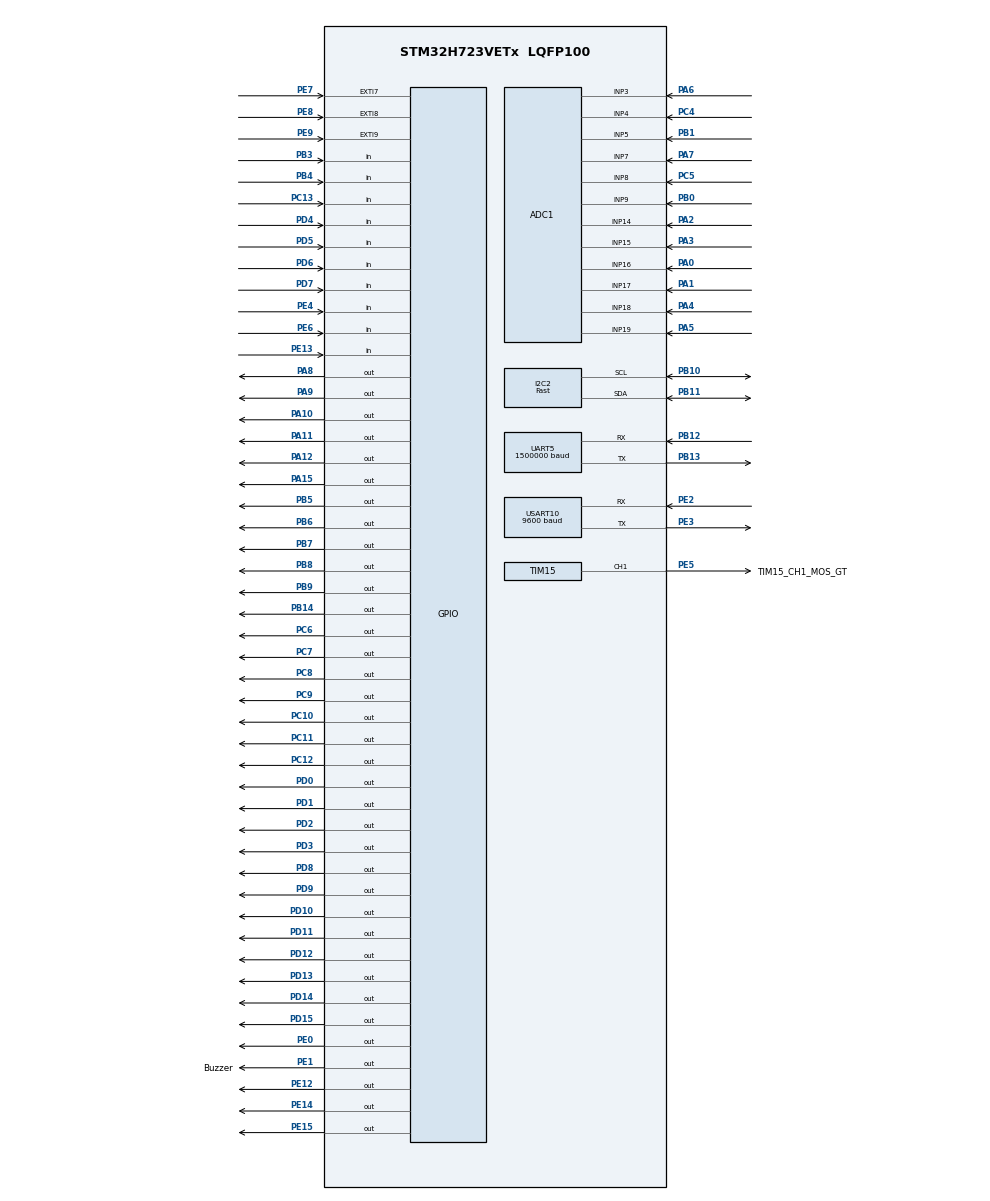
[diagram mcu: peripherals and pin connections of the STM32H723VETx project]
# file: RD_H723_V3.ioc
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ADC1.Channel-0\#ChannelRegularConversion=ADC_CHANNEL_5
ADC1.Channel-1\#ChannelRegularConversion=ADC_CHANNEL_16
ADC1.Channel-10\#ChannelRegularConversion=ADC_CHANNEL_9
ADC1.Channel-11\#ChannelRegularConversion=ADC_CHANNEL_3
ADC1.Channel-2\#ChannelRegularConversion=ADC_CHANNEL_17
ADC1.Channel-3\#ChannelRegularConversion=ADC_CHANNEL_14
ADC1.Channel-4\#ChannelRegularConversion=ADC_CHANNEL_15
ADC1.Channel-5\#ChannelRegularConversion=ADC_CHANNEL_18
ADC1.Channel-6\#ChannelRegularConversion=ADC_CHANNEL_19
ADC1.Channel-7\#ChannelRegularConversion=ADC_CHANNEL_8
ADC1.Channel-8\#ChannelRegularConversion=ADC_CHANNEL_7
ADC1.Channel-9\#ChannelRegularConversion=ADC_CHANNEL_4
ADC1.ClockPrescaler=ADC_CLOCK_ASYNC_DIV4
ADC1.ConversionDataManagement=ADC_CONVERSIONDATA_DMA_ONESHOT
ADC1.ExternalTrigConv=ADC_EXTERNALTRIG_T6_TRGO
ADC1.NbrOfConversion=12
ADC1.NbrOfConversionFlag=1
ADC1.OffsetNumber-0\#ChannelRegularConversion=ADC_OFFSET_NONE
ADC1.OffsetNumber-1\#ChannelRegularConversion=ADC_OFFSET_NONE
ADC1.OffsetNumber-10\#ChannelRegularConversion=ADC_OFFSET_NONE
ADC1.OffsetNumber-11\#ChannelRegularConversion=ADC_OFFSET_NONE
ADC1.OffsetNumber-2\#ChannelRegularConversion=ADC_OFFSET_NONE
ADC1.OffsetNumber-3\#ChannelRegularConversion=ADC_OFFSET_NONE
ADC1.OffsetNumber-4\#ChannelRegularConversion=ADC_OFFSET_NONE
ADC1.OffsetNumber-5\#ChannelRegularConversion=ADC_OFFSET_NONE
ADC1.OffsetNumber-6\#ChannelRegularConversion=ADC_OFFSET_NONE
ADC1.OffsetNumber-7\#ChannelRegularConversion=ADC_OFFSET_NONE
ADC1.OffsetNumber-8\#ChannelRegularConversion=ADC_OFFSET_NONE
ADC1.OffsetNumber-9\#ChannelRegularConversion=ADC_OFFSET_NONE
ADC1.OffsetSignedSaturation-0\#ChannelRegularConversion=DISABLE
ADC1.OffsetSignedSaturation-1\#ChannelRegularConversion=DISABLE
ADC1.OffsetSignedSaturation-10\#ChannelRegularConversion=DISABLE
ADC1.OffsetSignedSaturation-11\#ChannelRegularConversion=DISABLE
ADC1.OffsetSignedSaturation-2\#ChannelRegularConversion=DISABLE
ADC1.OffsetSignedSaturation-3\#ChannelRegularConversion=DISABLE
ADC1.OffsetSignedSaturation-4\#ChannelRegularConversion=DISABLE
ADC1.OffsetSignedSaturation-5\#ChannelRegularConversion=DISABLE
ADC1.OffsetSignedSaturation-6\#ChannelRegularConversion=DISABLE
ADC1.OffsetSignedSaturation-7\#ChannelRegularConversion=DISABLE
ADC1.OffsetSignedSaturation-8\#ChannelRegularConversion=DISABLE
ADC1.OffsetSignedSaturation-9\#ChannelRegularConversion=DISABLE
ADC1.Rank-0\#ChannelRegularConversion=1
ADC1.Rank-1\#ChannelRegularConversion=2
ADC1.Rank-10\#ChannelRegularConversion=11
ADC1.Rank-11\#ChannelRegularConversion=12
ADC1.Rank-2\#ChannelRegularConversion=3
ADC1.Rank-3\#ChannelRegularConversion=4
ADC1.Rank-4\#ChannelRegularConversion=5
ADC1.Rank-5\#ChannelRegularConversion=6
ADC1.Rank-6\#ChannelRegularConversion=7
ADC1.Rank-7\#ChannelRegularConversion=8
ADC1.Rank-8\#ChannelRegularConversion=9
ADC1.Rank-9\#ChannelRegularConversion=10
ADC1.SamplingTime-0\#ChannelRegularConversion=ADC_SAMPLETIME_1CYCLE_5
ADC1.SamplingTime-1\#ChannelRegularConversion=ADC_SAMPLETIME_1CYCLE_5
ADC1.SamplingTime-10\#ChannelRegularConversion=ADC_SAMPLETIME_1CYCLE_5
ADC1.SamplingTime-11\#ChannelRegularConversion=ADC_SAMPLETIME_1CYCLE_5
ADC1.SamplingTime-2\#ChannelRegularConversion=ADC_SAMPLETIME_1CYCLE_5
ADC1.SamplingTime-3\#ChannelRegularConversion=ADC_SAMPLETIME_1CYCLE_5
ADC1.SamplingTime-4\#ChannelRegularConversion=ADC_SAMPLETIME_1CYCLE_5
ADC1.SamplingTime-5\#ChannelRegularConversion=ADC_SAMPLETIME_1CYCLE_5
ADC1.SamplingTime-6\#ChannelRegularConversion=ADC_SAMPLETIME_1CYCLE_5
ADC1.SamplingTime-7\#ChannelRegularConversion=ADC_SAMPLETIME_1CYCLE_5
ADC1.SamplingTime-8\#ChannelRegularConversion=ADC_SAMPLETIME_1CYCLE_5
ADC1.SamplingTime-9\#ChannelRegularConversion=ADC_SAMPLETIME_1CYCLE_5
ADC1.master=1
CORTEX_M7.CPU_ICache=Disabled
CORTEX_M7.default_mode_Activation=1
Dma.ADC1.1.Direction=DMA_PERIPH_TO_MEMORY
Dma.ADC1.1.EventEnable=DISABLE
Dma.ADC1.1.FIFOMode=DMA_FIFOMODE_DISABLE
Dma.ADC1.1.Instance=DMA1_Stream1
Dma.ADC1.1.MemDataAlignment=DMA_MDATAALIGN_HALFWORD
Dma.ADC1.1.MemInc=DMA_MINC_ENABLE
Dma.ADC1.1.Mode=DMA_NORMAL
Dma.ADC1.1.PeriphDataAlignment=DMA_PDATAALIGN_HALFWORD
Dma.ADC1.1.PeriphInc=DMA_PINC_DISABLE
Dma.ADC1.1.Polarity=HAL_DMAMUX_REQ_GEN_RISING
Dma.ADC1.1.Priority=DMA_PRIORITY_VERY_HIGH
Dma.ADC1.1.RequestNumber=1
Dma.ADC1.1.SignalID=NONE
Dma.ADC1.1.SyncEnable=DISABLE
Dma.ADC1.1.SyncPolarity=HAL_DMAMUX_SYNC_NO_EVENT
Dma.ADC1.1.SyncRequestNumber=1
Dma.ADC1.1.SyncSignalID=NONE
Dma.Request0=UART5_TX
Dma.Request1=ADC1
Dma.UART5_TX.0.Direction=DMA_MEMORY_TO_PERIPH
Dma.UART5_TX.0.EventEnable=DISABLE
Dma.UART5_TX.0.FIFOMode=DMA_FIFOMODE_DISABLE
Dma.UART5_TX.0.Instance=DMA1_Stream0
Dma.UART5_TX.0.MemDataAlignment=DMA_MDATAALIGN_BYTE
Dma.UART5_TX.0.MemInc=DMA_MINC_ENABLE
Dma.UART5_TX.0.Mode=DMA_NORMAL
Dma.UART5_TX.0.PeriphDataAlignment=DMA_PDATAALIGN_BYTE
Dma.UART5_TX.0.PeriphInc=DMA_PINC_DISABLE
Dma.UART5_TX.0.Polarity=HAL_DMAMUX_REQ_GEN_RISING
Dma.UART5_TX.0.Priority=DMA_PRIORITY_LOW
Dma.UART5_TX.0.RequestNumber=1
Dma.UART5_TX.0.SignalID=NONE
Dma.UART5_TX.0.SyncEnable=DISABLE
Dma.UART5_TX.0.SyncPolarity=HAL_DMAMUX_SYNC_NO_EVENT
Dma.UART5_TX.0.SyncRequestNumber=1
Dma.UART5_TX.0.SyncSignalID=NONE
I2C2.Analog_Filter=I2C_ANALOGFILTER_DISABLE
I2C2.I2C_Speed_Mode=I2C_Fast
I2C2.OwnAddress=111
I2C2.Timing=0x00D056FC
Mcu.Family=STM32H7
Mcu.Name=STM32H723VETx
Mcu.Package=LQFP100
NVIC.DMA1_Stream0_IRQn=true\:0\:0\:false\:false\:false\:false\:true\:true
NVIC.DMA1_Stream1_IRQn=true\:0\:0\:false\:false\:false\:false\:true\:true
NVIC.EXTI9_5_IRQn=true\:15\:0\:true\:false\:false\:true\:true\:true
NVIC.PriorityGroup=NVIC_PRIORITYGROUP_4
NVIC.TIM16_IRQn=true\:15\:0\:true\:false\:false\:true\:true\:true
NVIC.TIM1_UP_IRQn=true\:15\:0\:true\:false\:false\:true\:true\:true
NVIC.TIM23_IRQn=true\:15\:0\:true\:false\:false\:true\:true\:true
NVIC.TIM24_IRQn=true\:15\:0\:true\:false\:false\:true\:true\:true
NVIC.TIM2_IRQn=true\:15\:0\:true\:false\:false\:true\:true\:true
NVIC.TIM3_IRQn=true\:15\:0\:true\:false\:false\:true\:true\:true
NVIC.TIM7_IRQn=true\:15\:0\:true\:false\:false\:true\:true\:true
NVIC.USART10_IRQn=true\:15\:0\:true\:false\:false\:true\:true\:true
PA0.Mode=IN16-Single-Ended
PA0.Signal=ADC1_INP16
PA1.Mode=IN17-Single-Ended
PA1.Signal=ADC1_INP17
PA10.Signal=GPIO_Output
PA11.Signal=GPIO_Output
PA12.Signal=GPIO_Output
PA13(JTMS/SWDIO).Mode=Serial_Wire
PA13(JTMS/SWDIO).Signal=DEBUG_JTMS-SWDIO
PA14(JTCK/SWCLK).Mode=Serial_Wire
PA14(JTCK/SWCLK).Signal=DEBUG_JTCK-SWCLK
PA15(JTDI).Signal=GPIO_Output
PA2.Signal=ADCx_INP14
PA3.Signal=ADCx_INP15
PA4.Signal=ADCx_INP18
PA5.Signal=ADCx_INP19
PA6.Signal=ADCx_INP3
PA7.Signal=ADCx_INP7
PA8.Signal=GPIO_Output
PA9.Signal=GPIO_Output
PB0.Signal=ADCx_INP9
PB1.Signal=ADCx_INP5
PB10.Mode=I2C
PB10.Signal=I2C2_SCL
PB11.Mode=I2C
PB11.Signal=I2C2_SDA
PB12.GPIO_ModeDefaultPP=GPIO_MODE_AF_OD
PB12.GPIO_PuPd=GPIO_PULLDOWN
PB12.Mode=Asynchronous
PB12.Signal=UART5_RX
PB13.GPIO_ModeDefaultPP=GPIO_MODE_AF_PP
PB13.Mode=Asynchronous
PB13.Signal=UART5_TX
PB14.Signal=GPIO_Output
PB3(JTDO/TRACESWO).Signal=GPIO_Input
PB4(NJTRST).Signal=GPIO_Input
PB5.Signal=GPIO_Output
PB6.Signal=GPIO_Output
PB7.Signal=GPIO_Output
PB8.Signal=GPIO_Output
PB9.Signal=GPIO_Output
PC10.Signal=GPIO_Output
PC11.Signal=GPIO_Output
PC12.Signal=GPIO_Output
PC13.Signal=GPIO_Input
PC4.Signal=ADCx_INP4
PC5.Signal=ADCx_INP8
PC6.Signal=GPIO_Output
PC7.Signal=GPIO_Output
PC8.Signal=GPIO_Output
PC9.Signal=GPIO_Output
PD0.Signal=GPIO_Output
PD1.Signal=GPIO_Output
PD10.Signal=GPIO_Output
PD11.Signal=GPIO_Output
PD12.Signal=GPIO_Output
PD13.Signal=GPIO_Output
PD14.Signal=GPIO_Output
PD15.Signal=GPIO_Output
PD2.Signal=GPIO_Output
PD3.Signal=GPIO_Output
PD4.Signal=GPIO_Input
PD5.Signal=GPIO_Input
PD6.Signal=GPIO_Input
PD7.Signal=GPIO_Input
PD8.Signal=GPIO_Output
PD9.Signal=GPIO_Output
PE0.Signal=GPIO_Output
PE1.GPIO_Label=Buzzer
PE1.PinState=GPIO_PIN_RESET
PE1.Signal=GPIO_Output
PE12.PinState=GPIO_PIN_RESET
PE12.Signal=GPIO_Output
PE13.Signal=GPIO_Input
PE14.Signal=GPIO_Output
PE15.Signal=GPIO_Output
PE2.GPIO_PuPd=GPIO_PULLDOWN
PE2.Mode=Asynchronous
PE2.Signal=USART10_RX
PE3.Mode=Asynchronous
PE3.Signal=USART10_TX
PE4.Signal=GPIO_Input
PE5.GPIO_Label=TIM15_CH1_MOS_GT
PE5.Signal=S_TIM15_CH1
PE6.Signal=GPIO_Input
PE7.Signal=GPXTI7
PE8.Signal=GPXTI8
PE9.Signal=GPXTI9
ProjectManager.HeapSize=0x200
ProjectManager.StackSize=0x400
ProjectManager.TargetToolchain=STM32CubeIDE
RCC.ADCFreq_Value=96000000
RCC.APB1Freq_Value=137500000
RCC.APB2Freq_Value=137500000
RCC.APB3Freq_Value=137500000
RCC.APB4Freq_Value=137500000
RCC.CortexFreq_Value=550000000
RCC.D1PPRE=RCC_APB3_DIV2
RCC.D2PPRE1=RCC_APB1_DIV2
RCC.D2PPRE2=RCC_APB2_DIV2
RCC.D3PPRE=RCC_APB4_DIV2
RCC.DIVM1=4
RCC.DIVM2=4
RCC.DIVN1=34
RCC.DIVN2=12
RCC.DIVP1=1
RCC.HCLKFreq_Value=275000000
RCC.HPRE=RCC_HCLK_DIV2
RCC.PLL2FRACN=0
RCC.PLL3FRACN=0
RCC.PLLFRACN=3072
RCC.SPI123CLockSelection=RCC_SPI123CLKSOURCE_CLKP
RCC.SYSCLKFreq_VALUE=550000000
RCC.SYSCLKSource=RCC_SYSCLKSOURCE_PLLCLK
RCC.Spi45ClockSelection=RCC_SPI45CLKSOURCE_HSI
RCC.USBFreq_Value=275000000
SH.ADCx_INP14.0=ADC1_INP14,IN14-Single-Ended
SH.ADCx_INP15.0=ADC1_INP15,IN15-Single-Ended
SH.ADCx_INP18.0=ADC1_INP18,IN18-Single-Ended
SH.ADCx_INP19.0=ADC1_INP19,IN19-Single-Ended
SH.ADCx_INP3.0=ADC1_INP3,IN3-Single-Ended
SH.ADCx_INP4.0=ADC1_INP4,IN4-Single-Ended
SH.ADCx_INP5.0=ADC1_INP5,IN5-Single-Ended
SH.ADCx_INP7.0=ADC1_INP7,IN7-Single-Ended
SH.ADCx_INP8.0=ADC1_INP8,IN8-Single-Ended
SH.ADCx_INP9.0=ADC1_INP9,IN9-Single-Ended
SH.S_TIM15_CH1.0=TIM15_CH1,PWM Generation1 CH1
TIM15.AutoReloadPreload=TIM_AUTORELOAD_PRELOAD_ENABLE
TIM15.Channel-PWM\ Generation1\ CH1=TIM_CHANNEL_1
TIM15.Pulse-PWM\ Generation1\ CH1=10000
TIM16.Channel=TIM_CHANNEL_1
TIM6.Period=54999
TIM6.Prescaler=4
TIM6.TIM_MasterOutputTrigger=TIM_TRGO_UPDATE
UART5.BaudRate=1500000
USART10.BaudRate=9600
USART10.SwapParam=ADVFEATURE_SWAP_ENABLE
USART10.VirtualMode=VM_ASYNC
VP_MEMORYMAP_VS_MEMORYMAP.Mode=CurAppReg
VP_TIM16_VS_ClockSourceINT.Mode=Enable_Timer
VP_TIM16_VS_no_output1.Mode=PWM Generation1 No Output
VP_TIM1_VS_ClockSourceINT.Mode=Internal
VP_TIM23_VS_ClockSourceINT.Mode=Internal
VP_TIM24_VS_ClockSourceINT.Mode=Internal
VP_TIM2_VS_ClockSourceINT.Mode=Internal
VP_TIM3_VS_ClockSourceINT.Mode=Internal
VP_TIM5_VS_ClockSourceINT.Mode=Internal
VP_TIM6_VS_ClockSourceINT.Mode=Enable_Timer
VP_TIM7_VS_ClockSourceINT.Mode=Enable_Timer
board=custom

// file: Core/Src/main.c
/* USER CODE BEGIN Header */
/**
  ******************************************************************************
  * @file           : main.c
  * @brief          : Main program body
  ******************************************************************************
  * @attention
  *
  * Copyright (c) 2024 STMicroelectronics.
  * All rights reserved.
  *
  * This software is licensed under terms that can be found in the LICENSE file
  * in the root directory of this software component.
  * If no LICENSE file comes with this software, it is provided AS-IS.
  *
  ******************************************************************************
  */
#include "_Includes.h"					////////////////////////////////////////////////////////
/* USER CODE END Header */
#include "main.h"

/* USER CODE BEGIN Includes */
#include "_DefConst_OK.h"					////////////////////////////////////////////////////////
#include "_DefConst.h"					////////////////////////////////////////////////////////
#include "_Fnc_Gen.h"					////////////////////////////////////////////////////////
#include "_Fnc_IRQ.h"					////////////////////////////////////////////////////////
/* USER CODE END Includes */

UART_HandleTypeDef huart10;

void SystemClock_Config(void);
void PeriphCommonClock_Config(void);
static void MPU_Config(void);
static void MX_GPIO_Init(void);
static void MX_DMA_Init(void);
static void MX_TIM15_Init(void);
static void MX_UART5_Init(void);
static void MX_TIM7_Init(void);
static void MX_I2C2_Init(void);
static void MX_ADC1_Init(void);
static void MX_TIM2_Init(void);
static void MX_TIM3_Init(void);
static void MX_TIM5_Init(void);
static void MX_TIM6_Init(void);
static void MX_TIM16_Init(void);
static void MX_TIM23_Init(void);
static void MX_TIM24_Init(void);
static void MX_USART10_UART_Init(void);
static void MX_TIM1_Init(void);

int main(void)
{

  /* MPU Configuration--------------------------------------------------------*/
  MPU_Config();

  /* MCU Configuration--------------------------------------------------------*/

  /* Reset of all peripherals, Initializes the Flash interface and the Systick. */
  HAL_Init();

  /* Configure the system clock */
  SystemClock_Config();

  /* Configure the peripherals common clocks */
  PeriphCommonClock_Config();

  /* Initialize all configured peripherals */
  MX_GPIO_Init();
  MX_DMA_Init();
  MX_TIM15_Init();
  MX_UART5_Init();
  MX_TIM7_Init();
  MX_I2C2_Init();
  MX_ADC1_Init();
  MX_TIM2_Init();
  MX_TIM3_Init();
  MX_TIM5_Init();
  MX_TIM6_Init();
  MX_TIM16_Init();
  MX_TIM23_Init();
  MX_TIM24_Init();
  MX_USART10_UART_Init();
  MX_TIM1_Init();
  /* USER CODE BEGIN 2 */
#include "_Set_Timers.h"				////////////////////////////////////////////////////////
#include "_Main.h"						////////////////////////////////////////////////////////
  /* USER CODE END 2 */

  /* Infinite loop */
  while (1)
  {

    /* USER CODE BEGIN 3 */
#include "_While.h"						////////////////////////////////////////////////////////
  }
  /* USER CODE END 3 */
}

void SystemClock_Config(void)
{
  LL_FLASH_SetLatency(LL_FLASH_LATENCY_3);
  while(LL_FLASH_GetLatency()!= LL_FLASH_LATENCY_3)
  {
  }
  LL_PWR_ConfigSupply(LL_PWR_LDO_SUPPLY);
  LL_PWR_SetRegulVoltageScaling(LL_PWR_REGU_VOLTAGE_SCALE0);
  while (LL_PWR_IsActiveFlag_VOS() == 0)
  {
  }
  LL_RCC_HSI_Enable();

   /* Wait till HSI is ready */
  while(LL_RCC_HSI_IsReady() != 1)
  {

  }
  LL_RCC_HSI_SetCalibTrimming(64);
  LL_RCC_HSI_SetDivider(LL_RCC_HSI_DIV1);
  LL_RCC_PLL_SetSource(LL_RCC_PLLSOURCE_HSI);
  LL_RCC_PLL1P_Enable();
  LL_RCC_PLL1R_Enable();
  LL_RCC_PLL1_SetVCOInputRange(LL_RCC_PLLINPUTRANGE_8_16);
  LL_RCC_PLL1_SetVCOOutputRange(LL_RCC_PLLVCORANGE_WIDE);
  LL_RCC_PLL1_SetM(4);
  LL_RCC_PLL1_SetN(34);
  LL_RCC_PLL1_SetP(1);
  LL_RCC_PLL1_SetQ(2);
  LL_RCC_PLL1_SetR(2);
  LL_RCC_PLL1_SetFRACN(3072);
  LL_RCC_PLL1FRACN_Enable();
  LL_RCC_PLL1_Enable();

   /* Wait till PLL is ready */
  while(LL_RCC_PLL1_IsReady() != 1)
  {
  }

   /* Intermediate AHB prescaler 2 when target frequency clock is higher than 80 MHz */
   LL_RCC_SetAHBPrescaler(LL_RCC_AHB_DIV_2);

  LL_RCC_SetSysClkSource(LL_RCC_SYS_CLKSOURCE_PLL1);

   /* Wait till System clock is ready */
  while(LL_RCC_GetSysClkSource() != LL_RCC_SYS_CLKSOURCE_STATUS_PLL1)
  {

  }
  LL_RCC_SetSysPrescaler(LL_RCC_SYSCLK_DIV_1);
  LL_RCC_SetAHBPrescaler(LL_RCC_AHB_DIV_2);
  LL_RCC_SetAPB1Prescaler(LL_RCC_APB1_DIV_2);
  LL_RCC_SetAPB2Prescaler(LL_RCC_APB2_DIV_2);
  LL_RCC_SetAPB3Prescaler(LL_RCC_APB3_DIV_2);
  LL_RCC_SetAPB4Prescaler(LL_RCC_APB4_DIV_2);
  LL_SetSystemCoreClock(550000000);

   /* Update the time base */
  if (HAL_InitTick (TICK_INT_PRIORITY) != HAL_OK)
  {
    Error_Handler();
  }
}

void PeriphCommonClock_Config(void)
{
  LL_RCC_PLL2P_Enable();
  LL_RCC_PLL2_SetVCOInputRange(LL_RCC_PLLINPUTRANGE_8_16);
  LL_RCC_PLL2_SetVCOOutputRange(LL_RCC_PLLVCORANGE_WIDE);
  LL_RCC_PLL2_SetM(4);
  LL_RCC_PLL2_SetN(12);
  LL_RCC_PLL2_SetP(2);
  LL_RCC_PLL2_SetQ(2);
  LL_RCC_PLL2_SetR(2);
  LL_RCC_PLL2_Enable();

   /* Wait till PLL is ready */
  while(LL_RCC_PLL2_IsReady() != 1)
  {
  }

}

static void MX_ADC1_Init(void)
{

  LL_ADC_InitTypeDef ADC_InitStruct = {0};
  LL_ADC_REG_InitTypeDef ADC_REG_InitStruct = {0};
  LL_ADC_CommonInitTypeDef ADC_CommonInitStruct = {0};

  LL_GPIO_InitTypeDef GPIO_InitStruct = {0};

  LL_RCC_SetADCClockSource(LL_RCC_ADC_CLKSOURCE_PLL2P);

  /* Peripheral clock enable */
  LL_AHB1_GRP1_EnableClock(LL_AHB1_GRP1_PERIPH_ADC12);

  LL_AHB4_GRP1_EnableClock(LL_AHB4_GRP1_PERIPH_GPIOA);
  LL_AHB4_GRP1_EnableClock(LL_AHB4_GRP1_PERIPH_GPIOC);
  LL_AHB4_GRP1_EnableClock(LL_AHB4_GRP1_PERIPH_GPIOB);
  /**ADC1 GPIO Configuration
  PA0   ------> ADC1_INP16
  PA1   ------> ADC1_INP17
  PA2   ------> ADC1_INP14
  PA3   ------> ADC1_INP15
  PA4   ------> ADC1_INP18
  PA5   ------> ADC1_INP19
  PA6   ------> ADC1_INP3
  PA7   ------> ADC1_INP7
  PC4   ------> ADC1_INP4
  PC5   ------> ADC1_INP8
  PB0   ------> ADC1_INP9
  PB1   ------> ADC1_INP5
  */
  GPIO_InitStruct.Pin = LL_GPIO_PIN_0|LL_GPIO_PIN_1|LL_GPIO_PIN_2|LL_GPIO_PIN_3
                          |LL_GPIO_PIN_4|LL_GPIO_PIN_5|LL_GPIO_PIN_6|LL_GPIO_PIN_7;
  GPIO_InitStruct.Mode = LL_GPIO_MODE_ANALOG;
  GPIO_InitStruct.Pull = LL_GPIO_PULL_NO;
  LL_GPIO_Init(GPIOA, &GPIO_InitStruct);

  GPIO_InitStruct.Pin = LL_GPIO_PIN_4|LL_GPIO_PIN_5;
  GPIO_InitStruct.Mode = LL_GPIO_MODE_ANALOG;
  GPIO_InitStruct.Pull = LL_GPIO_PULL_NO;
  LL_GPIO_Init(GPIOC, &GPIO_InitStruct);

  GPIO_InitStruct.Pin = LL_GPIO_PIN_0|LL_GPIO_PIN_1;
  GPIO_InitStruct.Mode = LL_GPIO_MODE_ANALOG;
  GPIO_InitStruct.Pull = LL_GPIO_PULL_NO;
  LL_GPIO_Init(GPIOB, &GPIO_InitStruct);

  /* ADC1 DMA Init */

  /* ADC1 Init */
  LL_DMA_SetPeriphRequest(DMA1, LL_DMA_STREAM_1, LL_DMAMUX1_REQ_ADC1);

  LL_DMA_SetDataTransferDirection(DMA1, LL_DMA_STREAM_1, LL_DMA_DIRECTION_PERIPH_TO_MEMORY);

  LL_DMA_SetStreamPriorityLevel(DMA1, LL_DMA_STREAM_1, LL_DMA_PRIORITY_VERYHIGH);

  LL_DMA_SetMode(DMA1, LL_DMA_STREAM_1, LL_DMA_MODE_NORMAL);

  LL_DMA_SetPeriphIncMode(DMA1, LL_DMA_STREAM_1, LL_DMA_PERIPH_NOINCREMENT);

  LL_DMA_SetMemoryIncMode(DMA1, LL_DMA_STREAM_1, LL_DMA_MEMORY_INCREMENT);

  LL_DMA_SetPeriphSize(DMA1, LL_DMA_STREAM_1, LL_DMA_PDATAALIGN_HALFWORD);

  LL_DMA_SetMemorySize(DMA1, LL_DMA_STREAM_1, LL_DMA_MDATAALIGN_HALFWORD);

  LL_DMA_DisableFifoMode(DMA1, LL_DMA_STREAM_1);

  /** Common config
  */
  LL_ADC_SetOverSamplingScope(ADC1, LL_ADC_OVS_DISABLE);
  ADC_InitStruct.Resolution = LL_ADC_RESOLUTION_16B;
  ADC_InitStruct.LowPowerMode = LL_ADC_LP_MODE_NONE;
  LL_ADC_Init(ADC1, &ADC_InitStruct);
  ADC_REG_InitStruct.TriggerSource = LL_ADC_REG_TRIG_EXT_TIM6_TRGO;
  ADC_REG_InitStruct.SequencerLength = LL_ADC_REG_SEQ_SCAN_ENABLE_12RANKS;
  ADC_REG_InitStruct.SequencerDiscont = DISABLE;
  ADC_REG_InitStruct.ContinuousMode = LL_ADC_REG_CONV_SINGLE;
  ADC_REG_InitStruct.Overrun = LL_ADC_REG_OVR_DATA_PRESERVED;
  LL_ADC_REG_Init(ADC1, &ADC_REG_InitStruct);
  LL_ADC_REG_SetDataTransferMode(ADC1, LL_ADC_REG_DMA_TRANSFER_LIMITED);
  ADC_CommonInitStruct.CommonClock = LL_ADC_CLOCK_ASYNC_DIV4;
  ADC_CommonInitStruct.Multimode = LL_ADC_MULTI_INDEPENDENT;
  LL_ADC_CommonInit(__LL_ADC_COMMON_INSTANCE(ADC1), &ADC_CommonInitStruct);
  LL_ADC_REG_SetTriggerEdge(ADC1, LL_ADC_REG_TRIG_EXT_RISING);

  /* Disable ADC deep power down (enabled by default after reset state) */
  LL_ADC_DisableDeepPowerDown(ADC1);
  /* Enable ADC internal voltage regulator */
  LL_ADC_EnableInternalRegulator(ADC1);
  /* Delay for ADC internal voltage regulator stabilization. */
  /* Compute number of CPU cycles to wait for, from delay in us. */
  /* Note: Variable divided by 2 to compensate partially */
  /* CPU processing cycles (depends on compilation optimization). */
  /* Note: If system core clock frequency is below 200kHz, wait time */
  /* is only a few CPU processing cycles. */
  __IO uint32_t wait_loop_index;
  wait_loop_index = ((LL_ADC_DELAY_INTERNAL_REGUL_STAB_US * (SystemCoreClock / (100000 * 2))) / 10);
  while(wait_loop_index != 0)
  {
    wait_loop_index--;
  }

  /** Configure Regular Channel
  */
  LL_ADC_REG_SetSequencerRanks(ADC1, LL_ADC_REG_RANK_1, LL_ADC_CHANNEL_5);
  LL_ADC_SetChannelSamplingTime(ADC1, LL_ADC_CHANNEL_5, LL_ADC_SAMPLINGTIME_1CYCLE_5);
  LL_ADC_SetChannelSingleDiff(ADC1, LL_ADC_CHANNEL_5, LL_ADC_SINGLE_ENDED);
  LL_ADC_SetChannelPreselection(ADC1, LL_ADC_CHANNEL_5);

  /** Configure Regular Channel
  */
  LL_ADC_REG_SetSequencerRanks(ADC1, LL_ADC_REG_RANK_2, LL_ADC_CHANNEL_16);
  LL_ADC_SetChannelSamplingTime(ADC1, LL_ADC_CHANNEL_16, LL_ADC_SAMPLINGTIME_1CYCLE_5);
  LL_ADC_SetChannelSingleDiff(ADC1, LL_ADC_CHANNEL_16, LL_ADC_SINGLE_ENDED);
  LL_ADC_SetChannelPreselection(ADC1, LL_ADC_CHANNEL_16);

  /** Configure Regular Channel
  */
  LL_ADC_REG_SetSequencerRanks(ADC1, LL_ADC_REG_RANK_3, LL_ADC_CHANNEL_17);
  LL_ADC_SetChannelSamplingTime(ADC1, LL_ADC_CHANNEL_17, LL_ADC_SAMPLINGTIME_1CYCLE_5);
  LL_ADC_SetChannelSingleDiff(ADC1, LL_ADC_CHANNEL_17, LL_ADC_SINGLE_ENDED);
  LL_ADC_SetChannelPreselection(ADC1, LL_ADC_CHANNEL_17);

  /** Configure Regular Channel
  */
  LL_ADC_REG_SetSequencerRanks(ADC1, LL_ADC_REG_RANK_4, LL_ADC_CHANNEL_14);
  LL_ADC_SetChannelSamplingTime(ADC1, LL_ADC_CHANNEL_14, LL_ADC_SAMPLINGTIME_1CYCLE_5);
  LL_ADC_SetChannelSingleDiff(ADC1, LL_ADC_CHANNEL_14, LL_ADC_SINGLE_ENDED);
  LL_ADC_SetChannelPreselection(ADC1, LL_ADC_CHANNEL_14);

  /** Configure Regular Channel
  */
  LL_ADC_REG_SetSequencerRanks(ADC1, LL_ADC_REG_RANK_5, LL_ADC_CHANNEL_15);
  LL_ADC_SetChannelSamplingTime(ADC1, LL_ADC_CHANNEL_15, LL_ADC_SAMPLINGTIME_1CYCLE_5);
  LL_ADC_SetChannelSingleDiff(ADC1, LL_ADC_CHANNEL_15, LL_ADC_SINGLE_ENDED);
  LL_ADC_SetChannelPreselection(ADC1, LL_ADC_CHANNEL_15);

  /** Configure Regular Channel
  */
  LL_ADC_REG_SetSequencerRanks(ADC1, LL_ADC_REG_RANK_6, LL_ADC_CHANNEL_18);
  LL_ADC_SetChannelSamplingTime(ADC1, LL_ADC_CHANNEL_18, LL_ADC_SAMPLINGTIME_1CYCLE_5);
  LL_ADC_SetChannelSingleDiff(ADC1, LL_ADC_CHANNEL_18, LL_ADC_SINGLE_ENDED);
  LL_ADC_SetChannelPreselection(ADC1, LL_ADC_CHANNEL_18);

  /** Configure Regular Channel
  */
  LL_ADC_REG_SetSequencerRanks(ADC1, LL_ADC_REG_RANK_7, LL_ADC_CHANNEL_19);
  LL_ADC_SetChannelSamplingTime(ADC1, LL_ADC_CHANNEL_19, LL_ADC_SAMPLINGTIME_1CYCLE_5);
  LL_ADC_SetChannelSingleDiff(ADC1, LL_ADC_CHANNEL_19, LL_ADC_SINGLE_ENDED);
  LL_ADC_SetChannelPreselection(ADC1, LL_ADC_CHANNEL_19);

  /** Configure Regular Channel
  */
  LL_ADC_REG_SetSequencerRanks(ADC1, LL_ADC_REG_RANK_8, LL_ADC_CHANNEL_8);
  LL_ADC_SetChannelSamplingTime(ADC1, LL_ADC_CHANNEL_8, LL_ADC_SAMPLINGTIME_1CYCLE_5);
  LL_ADC_SetChannelSingleDiff(ADC1, LL_ADC_CHANNEL_8, LL_ADC_SINGLE_ENDED);
  LL_ADC_SetChannelPreselection(ADC1, LL_ADC_CHANNEL_8);

  /** Configure Regular Channel
  */
  LL_ADC_REG_SetSequencerRanks(ADC1, LL_ADC_REG_RANK_9, LL_ADC_CHANNEL_7);
  LL_ADC_SetChannelSamplingTime(ADC1, LL_ADC_CHANNEL_7, LL_ADC_SAMPLINGTIME_1CYCLE_5);
  LL_ADC_SetChannelSingleDiff(ADC1, LL_ADC_CHANNEL_7, LL_ADC_SINGLE_ENDED);
  LL_ADC_SetChannelPreselection(ADC1, LL_ADC_CHANNEL_7);

  /** Configure Regular Channel
  */
  LL_ADC_REG_SetSequencerRanks(ADC1, LL_ADC_REG_RANK_10, LL_ADC_CHANNEL_4);
  LL_ADC_SetChannelSamplingTime(ADC1, LL_ADC_CHANNEL_4, LL_ADC_SAMPLINGTIME_1CYCLE_5);
  LL_ADC_SetChannelSingleDiff(ADC1, LL_ADC_CHANNEL_4, LL_ADC_SINGLE_ENDED);
  LL_ADC_SetChannelPreselection(ADC1, LL_ADC_CHANNEL_4);

  /** Configure Regular Channel
  */
  LL_ADC_REG_SetSequencerRanks(ADC1, LL_ADC_REG_RANK_11, LL_ADC_CHANNEL_9);
  LL_ADC_SetChannelSamplingTime(ADC1, LL_ADC_CHANNEL_9, LL_ADC_SAMPLINGTIME_1CYCLE_5);
  LL_ADC_SetChannelSingleDiff(ADC1, LL_ADC_CHANNEL_9, LL_ADC_SINGLE_ENDED);
  LL_ADC_SetChannelPreselection(ADC1, LL_ADC_CHANNEL_9);

  /** Configure Regular Channel
  */
  LL_ADC_REG_SetSequencerRanks(ADC1, LL_ADC_REG_RANK_12, LL_ADC_CHANNEL_3);
  LL_ADC_SetChannelSamplingTime(ADC1, LL_ADC_CHANNEL_3, LL_ADC_SAMPLINGTIME_1CYCLE_5);
  LL_ADC_SetChannelSingleDiff(ADC1, LL_ADC_CHANNEL_3, LL_ADC_SINGLE_ENDED);
  LL_ADC_SetChannelPreselection(ADC1, LL_ADC_CHANNEL_3);

}

static void MX_I2C2_Init(void)
{

  LL_I2C_InitTypeDef I2C_InitStruct = {0};

  LL_GPIO_InitTypeDef GPIO_InitStruct = {0};

  LL_RCC_SetI2CClockSource(LL_RCC_I2C123_CLKSOURCE_PCLK1);

  LL_AHB4_GRP1_EnableClock(LL_AHB4_GRP1_PERIPH_GPIOB);
  /**I2C2 GPIO Configuration
  PB10   ------> I2C2_SCL
  PB11   ------> I2C2_SDA
  */
  GPIO_InitStruct.Pin = LL_GPIO_PIN_10|LL_GPIO_PIN_11;
  GPIO_InitStruct.Mode = LL_GPIO_MODE_ALTERNATE;
  GPIO_InitStruct.Speed = LL_GPIO_SPEED_FREQ_LOW;
  GPIO_InitStruct.OutputType = LL_GPIO_OUTPUT_OPENDRAIN;
  GPIO_InitStruct.Pull = LL_GPIO_PULL_NO;
  GPIO_InitStruct.Alternate = LL_GPIO_AF_4;
  LL_GPIO_Init(GPIOB, &GPIO_InitStruct);

  /* Peripheral clock enable */
  LL_APB1_GRP1_EnableClock(LL_APB1_GRP1_PERIPH_I2C2);

  /** I2C Initialization
  */
  LL_I2C_EnableAutoEndMode(I2C2);
  LL_I2C_SetOwnAddress2(I2C2, 0, LL_I2C_OWNADDRESS2_NOMASK);
  LL_I2C_DisableOwnAddress2(I2C2);
  LL_I2C_DisableGeneralCall(I2C2);
  LL_I2C_EnableClockStretching(I2C2);
  I2C_InitStruct.PeripheralMode = LL_I2C_MODE_I2C;
  I2C_InitStruct.Timing = 0x00D056FC;
  I2C_InitStruct.AnalogFilter = LL_I2C_ANALOGFILTER_DISABLE;
  I2C_InitStruct.DigitalFilter = 0;
  I2C_InitStruct.OwnAddress1 = 222;
  I2C_InitStruct.TypeAcknowledge = LL_I2C_ACK;
  I2C_InitStruct.OwnAddrSize = LL_I2C_OWNADDRESS1_7BIT;
  LL_I2C_Init(I2C2, &I2C_InitStruct);

}

static void MX_TIM1_Init(void)
{

  LL_TIM_InitTypeDef TIM_InitStruct = {0};

  /* Peripheral clock enable */
  LL_APB2_GRP1_EnableClock(LL_APB2_GRP1_PERIPH_TIM1);

  /* TIM1 interrupt Init */
  NVIC_SetPriority(TIM1_UP_IRQn, NVIC_EncodePriority(NVIC_GetPriorityGrouping(),15, 0));
  NVIC_EnableIRQ(TIM1_UP_IRQn);

  TIM_InitStruct.Prescaler = 0;
  TIM_InitStruct.CounterMode = LL_TIM_COUNTERMODE_UP;
  TIM_InitStruct.Autoreload = 65535;
  TIM_InitStruct.ClockDivision = LL_TIM_CLOCKDIVISION_DIV1;
  TIM_InitStruct.RepetitionCounter = 0;
  LL_TIM_Init(TIM1, &TIM_InitStruct);
  LL_TIM_DisableARRPreload(TIM1);
  LL_TIM_SetClockSource(TIM1, LL_TIM_CLOCKSOURCE_INTERNAL);
  LL_TIM_SetTriggerOutput(TIM1, LL_TIM_TRGO_RESET);
  LL_TIM_SetTriggerOutput2(TIM1, LL_TIM_TRGO2_RESET);
  LL_TIM_DisableMasterSlaveMode(TIM1);

}

static void MX_TIM2_Init(void)
{

  LL_TIM_InitTypeDef TIM_InitStruct = {0};

  /* Peripheral clock enable */
  LL_APB1_GRP1_EnableClock(LL_APB1_GRP1_PERIPH_TIM2);

  /* TIM2 interrupt Init */
  NVIC_SetPriority(TIM2_IRQn, NVIC_EncodePriority(NVIC_GetPriorityGrouping(),15, 0));
  NVIC_EnableIRQ(TIM2_IRQn);

  TIM_InitStruct.Prescaler = 0;
  TIM_InitStruct.CounterMode = LL_TIM_COUNTERMODE_UP;
  TIM_InitStruct.Autoreload = 4294967295;
  TIM_InitStruct.ClockDivision = LL_TIM_CLOCKDIVISION_DIV1;
  LL_TIM_Init(TIM2, &TIM_InitStruct);
  LL_TIM_DisableARRPreload(TIM2);
  LL_TIM_SetClockSource(TIM2, LL_TIM_CLOCKSOURCE_INTERNAL);
  LL_TIM_SetTriggerOutput(TIM2, LL_TIM_TRGO_RESET);
  LL_TIM_DisableMasterSlaveMode(TIM2);

}

static void MX_TIM3_Init(void)
{

  LL_TIM_InitTypeDef TIM_InitStruct = {0};

  /* Peripheral clock enable */
  LL_APB1_GRP1_EnableClock(LL_APB1_GRP1_PERIPH_TIM3);

  /* TIM3 interrupt Init */
  NVIC_SetPriority(TIM3_IRQn, NVIC_EncodePriority(NVIC_GetPriorityGrouping(),15, 0));
  NVIC_EnableIRQ(TIM3_IRQn);

  TIM_InitStruct.Prescaler = 0;
  TIM_InitStruct.CounterMode = LL_TIM_COUNTERMODE_UP;
  TIM_InitStruct.Autoreload = 65535;
  TIM_InitStruct.ClockDivision = LL_TIM_CLOCKDIVISION_DIV1;
  LL_TIM_Init(TIM3, &TIM_InitStruct);
  LL_TIM_DisableARRPreload(TIM3);
  LL_TIM_SetClockSource(TIM3, LL_TIM_CLOCKSOURCE_INTERNAL);
  LL_TIM_SetTriggerOutput(TIM3, LL_TIM_TRGO_RESET);
  LL_TIM_DisableMasterSlaveMode(TIM3);

}

static void MX_TIM5_Init(void)
{

  LL_TIM_InitTypeDef TIM_InitStruct = {0};

  /* Peripheral clock enable */
  LL_APB1_GRP1_EnableClock(LL_APB1_GRP1_PERIPH_TIM5);

  TIM_InitStruct.Prescaler = 0;
  TIM_InitStruct.CounterMode = LL_TIM_COUNTERMODE_UP;
  TIM_InitStruct.Autoreload = 4294967295;
  TIM_InitStruct.ClockDivision = LL_TIM_CLOCKDIVISION_DIV1;
  LL_TIM_Init(TIM5, &TIM_InitStruct);
  LL_TIM_DisableARRPreload(TIM5);
  LL_TIM_SetClockSource(TIM5, LL_TIM_CLOCKSOURCE_INTERNAL);
  LL_TIM_SetTriggerOutput(TIM5, LL_TIM_TRGO_RESET);
  LL_TIM_DisableMasterSlaveMode(TIM5);

}

static void MX_TIM6_Init(void)
{

  LL_TIM_InitTypeDef TIM_InitStruct = {0};

  /* Peripheral clock enable */
  LL_APB1_GRP1_EnableClock(LL_APB1_GRP1_PERIPH_TIM6);

  TIM_InitStruct.Prescaler = 4;
  TIM_InitStruct.CounterMode = LL_TIM_COUNTERMODE_UP;
  TIM_InitStruct.Autoreload = 54999;
  LL_TIM_Init(TIM6, &TIM_InitStruct);
  LL_TIM_DisableARRPreload(TIM6);
  LL_TIM_SetTriggerOutput(TIM6, LL_TIM_TRGO_UPDATE);
  LL_TIM_DisableMasterSlaveMode(TIM6);

}

static void MX_TIM7_Init(void)
{

  LL_TIM_InitTypeDef TIM_InitStruct = {0};

  /* Peripheral clock enable */
  LL_APB1_GRP1_EnableClock(LL_APB1_GRP1_PERIPH_TIM7);

  /* TIM7 interrupt Init */
  NVIC_SetPriority(TIM7_IRQn, NVIC_EncodePriority(NVIC_GetPriorityGrouping(),15, 0));
  NVIC_EnableIRQ(TIM7_IRQn);

  TIM_InitStruct.Prescaler = 0;
  TIM_InitStruct.CounterMode = LL_TIM_COUNTERMODE_UP;
  TIM_InitStruct.Autoreload = 65535;
  LL_TIM_Init(TIM7, &TIM_InitStruct);
  LL_TIM_DisableARRPreload(TIM7);
  LL_TIM_SetTriggerOutput(TIM7, LL_TIM_TRGO_RESET);
  LL_TIM_DisableMasterSlaveMode(TIM7);

}

static void MX_TIM15_Init(void)
{

  LL_TIM_InitTypeDef TIM_InitStruct = {0};
  LL_TIM_OC_InitTypeDef TIM_OC_InitStruct = {0};
  LL_TIM_BDTR_InitTypeDef TIM_BDTRInitStruct = {0};

  LL_GPIO_InitTypeDef GPIO_InitStruct = {0};

  /* Peripheral clock enable */
  LL_APB2_GRP1_EnableClock(LL_APB2_GRP1_PERIPH_TIM15);

  TIM_InitStruct.Prescaler = 0;
  TIM_InitStruct.CounterMode = LL_TIM_COUNTERMODE_UP;
  TIM_InitStruct.Autoreload = 65535;
  TIM_InitStruct.ClockDivision = LL_TIM_CLOCKDIVISION_DIV1;
  TIM_InitStruct.RepetitionCounter = 0;
  LL_TIM_Init(TIM15, &TIM_InitStruct);
  LL_TIM_EnableARRPreload(TIM15);
  LL_TIM_OC_EnablePreload(TIM15, LL_TIM_CHANNEL_CH1);
  TIM_OC_InitStruct.OCMode = LL_TIM_OCMODE_PWM1;
  TIM_OC_InitStruct.OCState = LL_TIM_OCSTATE_DISABLE;
  TIM_OC_InitStruct.OCNState = LL_TIM_OCSTATE_DISABLE;
  TIM_OC_InitStruct.CompareValue = 10000;
  TIM_OC_InitStruct.OCPolarity = LL_TIM_OCPOLARITY_HIGH;
  TIM_OC_InitStruct.OCNPolarity = LL_TIM_OCPOLARITY_HIGH;
  TIM_OC_InitStruct.OCIdleState = LL_TIM_OCIDLESTATE_LOW;
  TIM_OC_InitStruct.OCNIdleState = LL_TIM_OCIDLESTATE_LOW;
  LL_TIM_OC_Init(TIM15, LL_TIM_CHANNEL_CH1, &TIM_OC_InitStruct);
  LL_TIM_OC_DisableFast(TIM15, LL_TIM_CHANNEL_CH1);
  LL_TIM_SetTriggerOutput(TIM15, LL_TIM_TRGO_RESET);
  LL_TIM_DisableMasterSlaveMode(TIM15);
  TIM_BDTRInitStruct.OSSRState = LL_TIM_OSSR_DISABLE;
  TIM_BDTRInitStruct.OSSIState = LL_TIM_OSSI_DISABLE;
  TIM_BDTRInitStruct.LockLevel = LL_TIM_LOCKLEVEL_OFF;
  TIM_BDTRInitStruct.DeadTime = 0;
  TIM_BDTRInitStruct.BreakState = LL_TIM_BREAK_DISABLE;
  TIM_BDTRInitStruct.BreakPolarity = LL_TIM_BREAK_POLARITY_HIGH;
  TIM_BDTRInitStruct.BreakFilter = LL_TIM_BREAK_FILTER_FDIV1;
  TIM_BDTRInitStruct.AutomaticOutput = LL_TIM_AUTOMATICOUTPUT_DISABLE;
  LL_TIM_BDTR_Init(TIM15, &TIM_BDTRInitStruct);
  LL_AHB4_GRP1_EnableClock(LL_AHB4_GRP1_PERIPH_GPIOE);
  /**TIM15 GPIO Configuration
  PE5   ------> TIM15_CH1
  */
  GPIO_InitStruct.Pin = TIM15_CH1_MOS_GT_Pin;
  GPIO_InitStruct.Mode = LL_GPIO_MODE_ALTERNATE;
  GPIO_InitStruct.Speed = LL_GPIO_SPEED_FREQ_LOW;
  GPIO_InitStruct.OutputType = LL_GPIO_OUTPUT_PUSHPULL;
  GPIO_InitStruct.Pull = LL_GPIO_PULL_NO;
  GPIO_InitStruct.Alternate = LL_GPIO_AF_4;
  LL_GPIO_Init(TIM15_CH1_MOS_GT_GPIO_Port, &GPIO_InitStruct);

}

static void MX_TIM16_Init(void)
{

  LL_TIM_InitTypeDef TIM_InitStruct = {0};
  LL_TIM_OC_InitTypeDef TIM_OC_InitStruct = {0};
  LL_TIM_BDTR_InitTypeDef TIM_BDTRInitStruct = {0};

  /* Peripheral clock enable */
  LL_APB2_GRP1_EnableClock(LL_APB2_GRP1_PERIPH_TIM16);

  /* TIM16 interrupt Init */
  NVIC_SetPriority(TIM16_IRQn, NVIC_EncodePriority(NVIC_GetPriorityGrouping(),15, 0));
  NVIC_EnableIRQ(TIM16_IRQn);

  TIM_InitStruct.Prescaler = 0;
  TIM_InitStruct.CounterMode = LL_TIM_COUNTERMODE_UP;
  TIM_InitStruct.Autoreload = 65535;
  TIM_InitStruct.ClockDivision = LL_TIM_CLOCKDIVISION_DIV1;
  TIM_InitStruct.RepetitionCounter = 0;
  LL_TIM_Init(TIM16, &TIM_InitStruct);
  LL_TIM_DisableARRPreload(TIM16);
  LL_TIM_OC_EnablePreload(TIM16, LL_TIM_CHANNEL_CH1);
  TIM_OC_InitStruct.OCMode = LL_TIM_OCMODE_PWM1;
  TIM_OC_InitStruct.OCState = LL_TIM_OCSTATE_DISABLE;
  TIM_OC_InitStruct.OCNState = LL_TIM_OCSTATE_DISABLE;
  TIM_OC_InitStruct.CompareValue = 0;
  TIM_OC_InitStruct.OCPolarity = LL_TIM_OCPOLARITY_HIGH;
  TIM_OC_InitStruct.OCNPolarity = LL_TIM_OCPOLARITY_HIGH;
  TIM_OC_InitStruct.OCIdleState = LL_TIM_OCIDLESTATE_LOW;
  TIM_OC_InitStruct.OCNIdleState = LL_TIM_OCIDLESTATE_LOW;
  LL_TIM_OC_Init(TIM16, LL_TIM_CHANNEL_CH1, &TIM_OC_InitStruct);
  LL_TIM_OC_DisableFast(TIM16, LL_TIM_CHANNEL_CH1);
  TIM_BDTRInitStruct.OSSRState = LL_TIM_OSSR_DISABLE;
  TIM_BDTRInitStruct.OSSIState = LL_TIM_OSSI_DISABLE;
  TIM_BDTRInitStruct.LockLevel = LL_TIM_LOCKLEVEL_OFF;
  TIM_BDTRInitStruct.DeadTime = 0;
  TIM_BDTRInitStruct.BreakState = LL_TIM_BREAK_DISABLE;
  TIM_BDTRInitStruct.BreakPolarity = LL_TIM_BREAK_POLARITY_HIGH;
  TIM_BDTRInitStruct.BreakFilter = LL_TIM_BREAK_FILTER_FDIV1;
  TIM_BDTRInitStruct.AutomaticOutput = LL_TIM_AUTOMATICOUTPUT_DISABLE;
  LL_TIM_BDTR_Init(TIM16, &TIM_BDTRInitStruct);

}

static void MX_TIM23_Init(void)
{

  LL_TIM_InitTypeDef TIM_InitStruct = {0};

  /* Peripheral clock enable */
  LL_APB1_GRP2_EnableClock(LL_APB1_GRP2_PERIPH_TIM23);

  /* TIM23 interrupt Init */
  NVIC_SetPriority(TIM23_IRQn, NVIC_EncodePriority(NVIC_GetPriorityGrouping(),15, 0));
  NVIC_EnableIRQ(TIM23_IRQn);

  TIM_InitStruct.Prescaler = 0;
  TIM_InitStruct.CounterMode = LL_TIM_COUNTERMODE_UP;
  TIM_InitStruct.Autoreload = 4294967295;
  TIM_InitStruct.ClockDivision = LL_TIM_CLOCKDIVISION_DIV1;
  LL_TIM_Init(TIM23, &TIM_InitStruct);
  LL_TIM_DisableARRPreload(TIM23);
  LL_TIM_SetClockSource(TIM23, LL_TIM_CLOCKSOURCE_INTERNAL);
  LL_TIM_SetTriggerOutput(TIM23, LL_TIM_TRGO_RESET);
  LL_TIM_DisableMasterSlaveMode(TIM23);

}

static void MX_TIM24_Init(void)
{

  LL_TIM_InitTypeDef TIM_InitStruct = {0};

  /* Peripheral clock enable */
  LL_APB1_GRP2_EnableClock(LL_APB1_GRP2_PERIPH_TIM24);

  /* TIM24 interrupt Init */
  NVIC_SetPriority(TIM24_IRQn, NVIC_EncodePriority(NVIC_GetPriorityGrouping(),15, 0));
  NVIC_EnableIRQ(TIM24_IRQn);

  TIM_InitStruct.Prescaler = 0;
  TIM_InitStruct.CounterMode = LL_TIM_COUNTERMODE_UP;
  TIM_InitStruct.Autoreload = 4294967295;
  TIM_InitStruct.ClockDivision = LL_TIM_CLOCKDIVISION_DIV1;
  LL_TIM_Init(TIM24, &TIM_InitStruct);
  LL_TIM_DisableARRPreload(TIM24);
  LL_TIM_SetClockSource(TIM24, LL_TIM_CLOCKSOURCE_INTERNAL);
  LL_TIM_SetTriggerOutput(TIM24, LL_TIM_TRGO_RESET);
  LL_TIM_DisableMasterSlaveMode(TIM24);

}

static void MX_UART5_Init(void)
{

  LL_USART_InitTypeDef UART_InitStruct = {0};

  LL_GPIO_InitTypeDef GPIO_InitStruct = {0};

  LL_RCC_SetUSARTClockSource(LL_RCC_USART234578_CLKSOURCE_PCLK1);

  /* Peripheral clock enable */
  LL_APB1_GRP1_EnableClock(LL_APB1_GRP1_PERIPH_UART5);

  LL_AHB4_GRP1_EnableClock(LL_AHB4_GRP1_PERIPH_GPIOB);
  /**UART5 GPIO Configuration
  PB12   ------> UART5_RX
  PB13   ------> UART5_TX
  */
  GPIO_InitStruct.Pin = LL_GPIO_PIN_12;
  GPIO_InitStruct.Mode = LL_GPIO_MODE_ALTERNATE;
  GPIO_InitStruct.Speed = LL_GPIO_SPEED_FREQ_LOW;
  GPIO_InitStruct.OutputType = LL_GPIO_OUTPUT_OPENDRAIN;
  GPIO_InitStruct.Pull = LL_GPIO_PULL_DOWN;
  GPIO_InitStruct.Alternate = LL_GPIO_AF_14;
  LL_GPIO_Init(GPIOB, &GPIO_InitStruct);

  GPIO_InitStruct.Pin = LL_GPIO_PIN_13;
  GPIO_InitStruct.Mode = LL_GPIO_MODE_ALTERNATE;
  GPIO_InitStruct.Speed = LL_GPIO_SPEED_FREQ_LOW;
  GPIO_InitStruct.OutputType = LL_GPIO_OUTPUT_PUSHPULL;
  GPIO_InitStruct.Pull = LL_GPIO_PULL_NO;
  GPIO_InitStruct.Alternate = LL_GPIO_AF_14;
  LL_GPIO_Init(GPIOB, &GPIO_InitStruct);

  /* UART5 DMA Init */

  /* UART5_TX Init */
  LL_DMA_SetPeriphRequest(DMA1, LL_DMA_STREAM_0, LL_DMAMUX1_REQ_UART5_TX);

  LL_DMA_SetDataTransferDirection(DMA1, LL_DMA_STREAM_0, LL_DMA_DIRECTION_MEMORY_TO_PERIPH);

  LL_DMA_SetStreamPriorityLevel(DMA1, LL_DMA_STREAM_0, LL_DMA_PRIORITY_LOW);

  LL_DMA_SetMode(DMA1, LL_DMA_STREAM_0, LL_DMA_MODE_NORMAL);

  LL_DMA_SetPeriphIncMode(DMA1, LL_DMA_STREAM_0, LL_DMA_PERIPH_NOINCREMENT);

  LL_DMA_SetMemoryIncMode(DMA1, LL_DMA_STREAM_0, LL_DMA_MEMORY_INCREMENT);

  LL_DMA_SetPeriphSize(DMA1, LL_DMA_STREAM_0, LL_DMA_PDATAALIGN_BYTE);

  LL_DMA_SetMemorySize(DMA1, LL_DMA_STREAM_0, LL_DMA_MDATAALIGN_BYTE);

  LL_DMA_DisableFifoMode(DMA1, LL_DMA_STREAM_0);

  UART_InitStruct.PrescalerValue = LL_USART_PRESCALER_DIV1;
  UART_InitStruct.BaudRate = 1500000;
  UART_InitStruct.DataWidth = LL_USART_DATAWIDTH_8B;
  UART_InitStruct.StopBits = LL_USART_STOPBITS_1;
  UART_InitStruct.Parity = LL_USART_PARITY_NONE;
  UART_InitStruct.TransferDirection = LL_USART_DIRECTION_TX_RX;
  UART_InitStruct.HardwareFlowControl = LL_USART_HWCONTROL_NONE;
  UART_InitStruct.OverSampling = LL_USART_OVERSAMPLING_16;
  LL_USART_Init(UART5, &UART_InitStruct);
  LL_USART_DisableFIFO(UART5);
  LL_USART_SetTXFIFOThreshold(UART5, LL_USART_FIFOTHRESHOLD_1_8);
  LL_USART_SetRXFIFOThreshold(UART5, LL_USART_FIFOTHRESHOLD_1_8);
  LL_USART_ConfigAsyncMode(UART5);

  LL_USART_Enable(UART5);

  /* Polling UART5 initialisation */
  while((!(LL_USART_IsActiveFlag_TEACK(UART5))) || (!(LL_USART_IsActiveFlag_REACK(UART5))))
  {
  }

}

static void MX_USART10_UART_Init(void)
{

  huart10.Instance = USART10;
  huart10.Init.BaudRate = 9600;
  huart10.Init.WordLength = UART_WORDLENGTH_8B;
  huart10.Init.StopBits = UART_STOPBITS_1;
  huart10.Init.Parity = UART_PARITY_NONE;
  huart10.Init.Mode = UART_MODE_TX_RX;
  huart10.Init.HwFlowCtl = UART_HWCONTROL_NONE;
  huart10.Init.OverSampling = UART_OVERSAMPLING_16;
  huart10.Init.OneBitSampling = UART_ONE_BIT_SAMPLE_DISABLE;
  huart10.Init.ClockPrescaler = UART_PRESCALER_DIV1;
  huart10.AdvancedInit.AdvFeatureInit = UART_ADVFEATURE_SWAP_INIT;
  huart10.AdvancedInit.Swap = UART_ADVFEATURE_SWAP_ENABLE;
  if (HAL_UART_Init(&huart10) != HAL_OK)
  {
    Error_Handler();
  }
  if (HAL_UARTEx_SetTxFifoThreshold(&huart10, UART_TXFIFO_THRESHOLD_1_8) != HAL_OK)
  {
    Error_Handler();
  }
  if (HAL_UARTEx_SetRxFifoThreshold(&huart10, UART_RXFIFO_THRESHOLD_1_8) != HAL_OK)
  {
    Error_Handler();
  }
  if (HAL_UARTEx_DisableFifoMode(&huart10) != HAL_OK)
  {
    Error_Handler();
  }

}

static void MX_DMA_Init(void)
{

  /* Init with LL driver */
  /* DMA controller clock enable */
  LL_AHB1_GRP1_EnableClock(LL_AHB1_GRP1_PERIPH_DMA1);

  /* DMA interrupt init */
  /* DMA1_Stream0_IRQn interrupt configuration */
  NVIC_SetPriority(DMA1_Stream0_IRQn, NVIC_EncodePriority(NVIC_GetPriorityGrouping(),0, 0));
  NVIC_EnableIRQ(DMA1_Stream0_IRQn);
  /* DMA1_Stream1_IRQn interrupt configuration */
  NVIC_SetPriority(DMA1_Stream1_IRQn, NVIC_EncodePriority(NVIC_GetPriorityGrouping(),0, 0));
  NVIC_EnableIRQ(DMA1_Stream1_IRQn);

}

static void MX_GPIO_Init(void)
{
  LL_EXTI_InitTypeDef EXTI_InitStruct = {0};
  LL_GPIO_InitTypeDef GPIO_InitStruct = {0};

  /* GPIO Ports Clock Enable */
  LL_AHB4_GRP1_EnableClock(LL_AHB4_GRP1_PERIPH_GPIOE);
  LL_AHB4_GRP1_EnableClock(LL_AHB4_GRP1_PERIPH_GPIOC);
  LL_AHB4_GRP1_EnableClock(LL_AHB4_GRP1_PERIPH_GPIOH);
  LL_AHB4_GRP1_EnableClock(LL_AHB4_GRP1_PERIPH_GPIOA);
  LL_AHB4_GRP1_EnableClock(LL_AHB4_GRP1_PERIPH_GPIOB);
  LL_AHB4_GRP1_EnableClock(LL_AHB4_GRP1_PERIPH_GPIOD);

  /**/
  LL_GPIO_ResetOutputPin(GPIOE, LL_GPIO_PIN_12|LL_GPIO_PIN_14|LL_GPIO_PIN_15|LL_GPIO_PIN_0
                          |Buzzer_Pin);

  /**/
  LL_GPIO_ResetOutputPin(GPIOB, LL_GPIO_PIN_14|LL_GPIO_PIN_5|LL_GPIO_PIN_6|LL_GPIO_PIN_7
                          |LL_GPIO_PIN_8|LL_GPIO_PIN_9);

  /**/
  LL_GPIO_ResetOutputPin(GPIOD, LL_GPIO_PIN_8|LL_GPIO_PIN_9|LL_GPIO_PIN_10|LL_GPIO_PIN_11
                          |LL_GPIO_PIN_12|LL_GPIO_PIN_13|LL_GPIO_PIN_14|LL_GPIO_PIN_15
                          |LL_GPIO_PIN_0|LL_GPIO_PIN_1|LL_GPIO_PIN_2|LL_GPIO_PIN_3);

  /**/
  LL_GPIO_ResetOutputPin(GPIOC, LL_GPIO_PIN_6|LL_GPIO_PIN_7|LL_GPIO_PIN_8|LL_GPIO_PIN_9
                          |LL_GPIO_PIN_10|LL_GPIO_PIN_11|LL_GPIO_PIN_12);

  /**/
  LL_GPIO_ResetOutputPin(GPIOA, LL_GPIO_PIN_8|LL_GPIO_PIN_9|LL_GPIO_PIN_10|LL_GPIO_PIN_11
                          |LL_GPIO_PIN_12|LL_GPIO_PIN_15);

  /**/
  GPIO_InitStruct.Pin = LL_GPIO_PIN_4|LL_GPIO_PIN_6|LL_GPIO_PIN_13;
  GPIO_InitStruct.Mode = LL_GPIO_MODE_INPUT;
  GPIO_InitStruct.Pull = LL_GPIO_PULL_NO;
  LL_GPIO_Init(GPIOE, &GPIO_InitStruct);

  /**/
  GPIO_InitStruct.Pin = LL_GPIO_PIN_13;
  GPIO_InitStruct.Mode = LL_GPIO_MODE_INPUT;
  GPIO_InitStruct.Pull = LL_GPIO_PULL_NO;
  LL_GPIO_Init(GPIOC, &GPIO_InitStruct);

  /**/
  GPIO_InitStruct.Pin = LL_GPIO_PIN_14|LL_GPIO_PIN_15|LL_GPIO_PIN_0|LL_GPIO_PIN_1
                          |LL_GPIO_PIN_2|LL_GPIO_PIN_3;
  GPIO_InitStruct.Mode = LL_GPIO_MODE_ANALOG;
  GPIO_InitStruct.Pull = LL_GPIO_PULL_NO;
  LL_GPIO_Init(GPIOC, &GPIO_InitStruct);

  /**/
  GPIO_InitStruct.Pin = LL_GPIO_PIN_0|LL_GPIO_PIN_1;
  GPIO_InitStruct.Mode = LL_GPIO_MODE_ANALOG;
  GPIO_InitStruct.Pull = LL_GPIO_PULL_NO;
  LL_GPIO_Init(GPIOH, &GPIO_InitStruct);

  /**/
  GPIO_InitStruct.Pin = LL_GPIO_PIN_2|LL_GPIO_PIN_15;
  GPIO_InitStruct.Mode = LL_GPIO_MODE_ANALOG;
  GPIO_InitStruct.Pull = LL_GPIO_PULL_NO;
  LL_GPIO_Init(GPIOB, &GPIO_InitStruct);

  /**/
  GPIO_InitStruct.Pin = LL_GPIO_PIN_10|LL_GPIO_PIN_11;
  GPIO_InitStruct.Mode = LL_GPIO_MODE_ANALOG;
  GPIO_InitStruct.Pull = LL_GPIO_PULL_NO;
  LL_GPIO_Init(GPIOE, &GPIO_InitStruct);

  /**/
  GPIO_InitStruct.Pin = LL_GPIO_PIN_12|LL_GPIO_PIN_14|LL_GPIO_PIN_15|LL_GPIO_PIN_0
                          |Buzzer_Pin;
  GPIO_InitStruct.Mode = LL_GPIO_MODE_OUTPUT;
  GPIO_InitStruct.Speed = LL_GPIO_SPEED_FREQ_LOW;
  GPIO_InitStruct.OutputType = LL_GPIO_OUTPUT_PUSHPULL;
  GPIO_InitStruct.Pull = LL_GPIO_PULL_NO;
  LL_GPIO_Init(GPIOE, &GPIO_InitStruct);

  /**/
  GPIO_InitStruct.Pin = LL_GPIO_PIN_14|LL_GPIO_PIN_5|LL_GPIO_PIN_6|LL_GPIO_PIN_7
                          |LL_GPIO_PIN_8|LL_GPIO_PIN_9;
  GPIO_InitStruct.Mode = LL_GPIO_MODE_OUTPUT;
  GPIO_InitStruct.Speed = LL_GPIO_SPEED_FREQ_LOW;
  GPIO_InitStruct.OutputType = LL_GPIO_OUTPUT_PUSHPULL;
  GPIO_InitStruct.Pull = LL_GPIO_PULL_NO;
  LL_GPIO_Init(GPIOB, &GPIO_InitStruct);

  /**/
  GPIO_InitStruct.Pin = LL_GPIO_PIN_8|LL_GPIO_PIN_9|LL_GPIO_PIN_10|LL_GPIO_PIN_11
                          |LL_GPIO_PIN_12|LL_GPIO_PIN_13|LL_GPIO_PIN_14|LL_GPIO_PIN_15
                          |LL_GPIO_PIN_0|LL_GPIO_PIN_1|LL_GPIO_PIN_2|LL_GPIO_PIN_3;
  GPIO_InitStruct.Mode = LL_GPIO_MODE_OUTPUT;
  GPIO_InitStruct.Speed = LL_GPIO_SPEED_FREQ_LOW;
  GPIO_InitStruct.OutputType = LL_GPIO_OUTPUT_PUSHPULL;
  GPIO_InitStruct.Pull = LL_GPIO_PULL_NO;
  LL_GPIO_Init(GPIOD, &GPIO_InitStruct);

  /**/
  GPIO_InitStruct.Pin = LL_GPIO_PIN_6|LL_GPIO_PIN_7|LL_GPIO_PIN_8|LL_GPIO_PIN_9
                          |LL_GPIO_PIN_10|LL_GPIO_PIN_11|LL_GPIO_PIN_12;
  GPIO_InitStruct.Mode = LL_GPIO_MODE_OUTPUT;
  GPIO_InitStruct.Speed = LL_GPIO_SPEED_FREQ_LOW;
  GPIO_InitStruct.OutputType = LL_GPIO_OUTPUT_PUSHPULL;
  GPIO_InitStruct.Pull = LL_GPIO_PULL_NO;
  LL_GPIO_Init(GPIOC, &GPIO_InitStruct);

  /**/
  GPIO_InitStruct.Pin = LL_GPIO_PIN_8|LL_GPIO_PIN_9|LL_GPIO_PIN_10|LL_GPIO_PIN_11
                          |LL_GPIO_PIN_12|LL_GPIO_PIN_15;
  GPIO_InitStruct.Mode = LL_GPIO_MODE_OUTPUT;
  GPIO_InitStruct.Speed = LL_GPIO_SPEED_FREQ_LOW;
  GPIO_InitStruct.OutputType = LL_GPIO_OUTPUT_PUSHPULL;
  GPIO_InitStruct.Pull = LL_GPIO_PULL_NO;
  LL_GPIO_Init(GPIOA, &GPIO_InitStruct);

  /**/
  GPIO_InitStruct.Pin = LL_GPIO_PIN_4|LL_GPIO_PIN_5|LL_GPIO_PIN_6|LL_GPIO_PIN_7;
  GPIO_InitStruct.Mode = LL_GPIO_MODE_INPUT;
  GPIO_InitStruct.Pull = LL_GPIO_PULL_NO;
  LL_GPIO_Init(GPIOD, &GPIO_InitStruct);

  /**/
  GPIO_InitStruct.Pin = LL_GPIO_PIN_3|LL_GPIO_PIN_4;
  GPIO_InitStruct.Mode = LL_GPIO_MODE_INPUT;
  GPIO_InitStruct.Pull = LL_GPIO_PULL_NO;
  LL_GPIO_Init(GPIOB, &GPIO_InitStruct);

  /**/
  LL_SYSCFG_SetEXTISource(LL_SYSCFG_EXTI_PORTE, LL_SYSCFG_EXTI_LINE7);

  /**/
  LL_SYSCFG_SetEXTISource(LL_SYSCFG_EXTI_PORTE, LL_SYSCFG_EXTI_LINE8);

  /**/
  LL_SYSCFG_SetEXTISource(LL_SYSCFG_EXTI_PORTE, LL_SYSCFG_EXTI_LINE9);

  /**/
  EXTI_InitStruct.Line_0_31 = LL_EXTI_LINE_7;
  EXTI_InitStruct.Line_32_63 = LL_EXTI_LINE_NONE;
  EXTI_InitStruct.Line_64_95 = LL_EXTI_LINE_NONE;
  EXTI_InitStruct.LineCommand = ENABLE;
  EXTI_InitStruct.Mode = LL_EXTI_MODE_IT;
  EXTI_InitStruct.Trigger = LL_EXTI_TRIGGER_RISING;
  LL_EXTI_Init(&EXTI_InitStruct);

  /**/
  EXTI_InitStruct.Line_0_31 = LL_EXTI_LINE_8;
  EXTI_InitStruct.Line_32_63 = LL_EXTI_LINE_NONE;
  EXTI_InitStruct.Line_64_95 = LL_EXTI_LINE_NONE;
  EXTI_InitStruct.LineCommand = ENABLE;
  EXTI_InitStruct.Mode = LL_EXTI_MODE_IT;
  EXTI_InitStruct.Trigger = LL_EXTI_TRIGGER_RISING;
  LL_EXTI_Init(&EXTI_InitStruct);

  /**/
  EXTI_InitStruct.Line_0_31 = LL_EXTI_LINE_9;
  EXTI_InitStruct.Line_32_63 = LL_EXTI_LINE_NONE;
  EXTI_InitStruct.Line_64_95 = LL_EXTI_LINE_NONE;
  EXTI_InitStruct.LineCommand = ENABLE;
  EXTI_InitStruct.Mode = LL_EXTI_MODE_IT;
  EXTI_InitStruct.Trigger = LL_EXTI_TRIGGER_RISING;
  LL_EXTI_Init(&EXTI_InitStruct);

  /**/
  LL_GPIO_SetPinPull(GPIOE, LL_GPIO_PIN_7, LL_GPIO_PULL_NO);

  /**/
  LL_GPIO_SetPinPull(GPIOE, LL_GPIO_PIN_8, LL_GPIO_PULL_NO);

  /**/
  LL_GPIO_SetPinPull(GPIOE, LL_GPIO_PIN_9, LL_GPIO_PULL_NO);

  /**/
  LL_GPIO_SetPinMode(GPIOE, LL_GPIO_PIN_7, LL_GPIO_MODE_INPUT);

  /**/
  LL_GPIO_SetPinMode(GPIOE, LL_GPIO_PIN_8, LL_GPIO_MODE_INPUT);

  /**/
  LL_GPIO_SetPinMode(GPIOE, LL_GPIO_PIN_9, LL_GPIO_MODE_INPUT);

  /* EXTI interrupt init*/
  NVIC_SetPriority(EXTI9_5_IRQn, NVIC_EncodePriority(NVIC_GetPriorityGrouping(),15, 0));
  NVIC_EnableIRQ(EXTI9_5_IRQn);

}

 /* MPU Configuration */

void MPU_Config(void)
{

  /* Disables the MPU */
  LL_MPU_Disable();

  /** Initializes and configures the Region and the memory to be protected
  */
  LL_MPU_ConfigRegion(LL_MPU_REGION_NUMBER0, 0x87, 0x0, LL_MPU_REGION_SIZE_4GB|LL_MPU_TEX_LEVEL0|LL_MPU_REGION_NO_ACCESS|LL_MPU_INSTRUCTION_ACCESS_DISABLE|LL_MPU_ACCESS_SHAREABLE|LL_MPU_ACCESS_NOT_CACHEABLE|LL_MPU_ACCESS_NOT_BUFFERABLE);
  /* Enables the MPU */
  LL_MPU_Enable(LL_MPU_CTRL_PRIVILEGED_DEFAULT);

}

void Error_Handler(void)
{
  __disable_irq();
  while (1)
  {
  }
}
